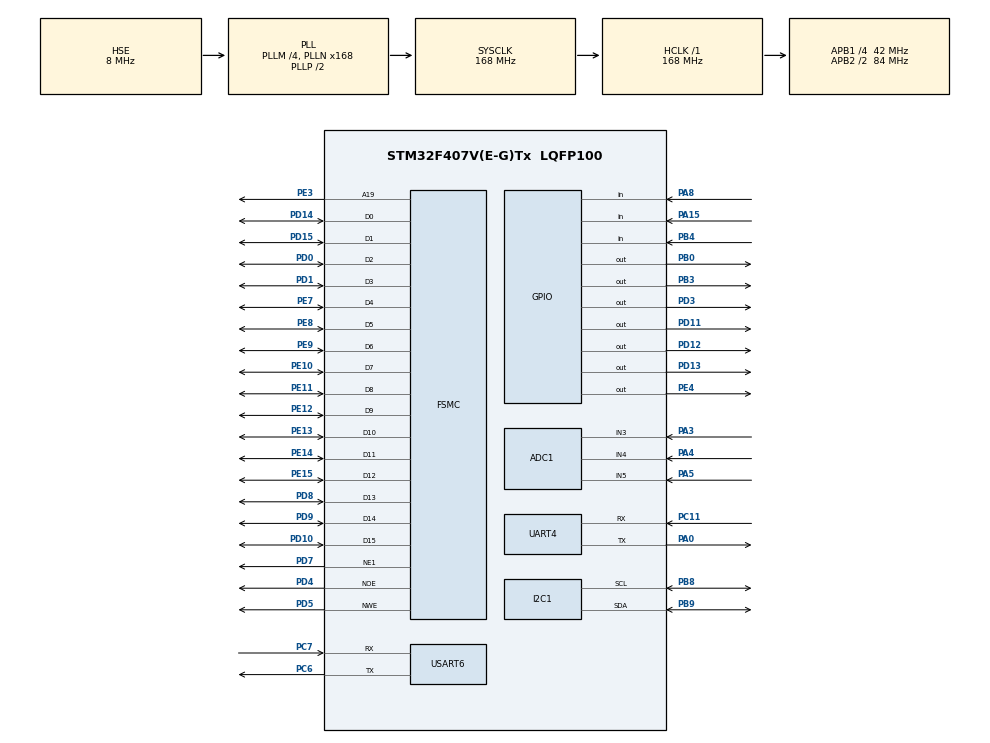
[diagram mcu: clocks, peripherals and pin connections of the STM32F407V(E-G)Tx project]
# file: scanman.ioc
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ADC1.Channel-0\#ChannelRegularConversion=ADC_CHANNEL_3
ADC1.Channel-1\#ChannelInjectedConversion=ADC_CHANNEL_3
ADC1.Channel-2\#ChannelInjectedConversion=ADC_CHANNEL_4
ADC1.Channel-3\#ChannelInjectedConversion=ADC_CHANNEL_5
ADC1.InjNumberOfConversion=3
ADC1.InjectedOffset-1\#ChannelInjectedConversion=0
ADC1.InjectedOffset-2\#ChannelInjectedConversion=0
ADC1.InjectedOffset-3\#ChannelInjectedConversion=0
ADC1.NbrOfConversionFlag=1
ADC1.Rank-0\#ChannelRegularConversion=1
ADC1.Rank-1\#ChannelInjectedConversion=1
ADC1.Rank-2\#ChannelInjectedConversion=2
ADC1.Rank-3\#ChannelInjectedConversion=3
ADC1.SamplingTime-0\#ChannelRegularConversion=ADC_SAMPLETIME_3CYCLES
ADC1.SamplingTime-1\#ChannelInjectedConversion=ADC_SAMPLETIME_3CYCLES
ADC1.SamplingTime-2\#ChannelInjectedConversion=ADC_SAMPLETIME_3CYCLES
ADC1.SamplingTime-3\#ChannelInjectedConversion=ADC_SAMPLETIME_3CYCLES
ADC1.master=1
FSMC.AddressSetupTime1=1
FSMC.BusTurnAroundDuration1=0
FSMC.DataSetupTime1=9
Mcu.Family=STM32F4
Mcu.Name=STM32F407V(E-G)Tx
Mcu.Package=LQFP100
NVIC.PriorityGroup=NVIC_PRIORITYGROUP_4
NVIC.UART4_IRQn=true\:0\:0\:false\:false\:true\:true
NVIC.USART6_IRQn=true\:0\:0\:false\:false\:true\:true
PA0-WKUP.Mode=Asynchronous
PA0-WKUP.Signal=UART4_TX
PA13.Mode=Serial_Wire
PA13.Signal=SYS_JTMS-SWDIO
PA14.Mode=Serial_Wire
PA14.Signal=SYS_JTCK-SWCLK
PA15.GPIO_PuPd=GPIO_PULLUP
PA15.Signal=GPIO_Input
PA3.Signal=ADCx_IN3
PA4.Signal=ADCx_IN4
PA5.Signal=ADCx_IN5
PA8.GPIO_PuPd=GPIO_PULLUP
PA8.Signal=GPIO_Input
PB0.PinState=GPIO_PIN_RESET
PB0.Signal=GPIO_Output
PB3.PinState=GPIO_PIN_SET
PB3.Signal=GPIO_Output
PB4.Signal=GPIO_Input
PB8.Mode=I2C
PB8.Signal=I2C1_SCL
PB9.Mode=I2C
PB9.Signal=I2C1_SDA
PC11.Mode=Asynchronous
PC11.Signal=UART4_RX
PC6.Mode=Asynchronous
PC6.Signal=USART6_TX
PC7.Mode=Asynchronous
PC7.Signal=USART6_RX
PD0.Mode=16b-d1
PD0.Signal=FSMC_D2
PD1.Mode=16b-d1
PD1.Signal=FSMC_D3
PD10.Mode=16b-d1
PD10.Signal=FSMC_D15
PD11.Signal=GPIO_Output
PD12.Signal=GPIO_Output
PD13.Signal=GPIO_Output
PD14.Mode=16b-d1
PD14.Signal=FSMC_D0
PD15.Mode=16b-d1
PD15.Signal=FSMC_D1
PD3.Signal=GPIO_Output
PD4.Mode=Lcd1
PD4.Signal=FSMC_NOE
PD5.Mode=Lcd1
PD5.Signal=FSMC_NWE
PD7.Mode=NorPsramChipSelect1_1
PD7.Signal=FSMC_NE1
PD8.Mode=16b-d1
PD8.Signal=FSMC_D13
PD9.Mode=16b-d1
PD9.Signal=FSMC_D14
PE10.Mode=16b-d1
PE10.Signal=FSMC_D7
PE11.Mode=16b-d1
PE11.Signal=FSMC_D8
PE12.Mode=16b-d1
PE12.Signal=FSMC_D9
PE13.Mode=16b-d1
PE13.Signal=FSMC_D10
PE14.Mode=16b-d1
PE14.Signal=FSMC_D11
PE15.Mode=16b-d1
PE15.Signal=FSMC_D12
PE3.Mode=A19_1
PE3.Signal=FSMC_A19
PE4.Signal=GPIO_Output
PE7.Mode=16b-d1
PE7.Signal=FSMC_D4
PE8.Mode=16b-d1
PE8.Signal=FSMC_D5
PE9.Mode=16b-d1
PE9.Signal=FSMC_D6
PH0-OSC_IN.Mode=HSE-External-Oscillator
PH0-OSC_IN.Signal=RCC_OSC_IN
PH1-OSC_OUT.Mode=HSE-External-Oscillator
PH1-OSC_OUT.Signal=RCC_OSC_OUT
ProjectManager.HeapSize=0x200
ProjectManager.StackSize=0x400
ProjectManager.TargetToolchain=EWARM V8
RCC.48MHZClocksFreq_Value=84000000
RCC.AHBFreq_Value=168000000
RCC.APB1CLKDivider=RCC_HCLK_DIV4
RCC.APB1Freq_Value=42000000
RCC.APB1TimFreq_Value=84000000
RCC.APB2CLKDivider=RCC_HCLK_DIV2
RCC.APB2Freq_Value=84000000
RCC.APB2TimFreq_Value=168000000
RCC.CortexFreq_Value=168000000
RCC.HCLKFreq_Value=168000000
RCC.HSE_VALUE=8000000
RCC.HSI_VALUE=16000000
RCC.LSE_VALUE=32768
RCC.PLLM=4
RCC.PLLN=168
RCC.PLLSourceVirtual=RCC_PLLSOURCE_HSE
RCC.SYSCLKFreq_VALUE=168000000
RCC.SYSCLKSource=RCC_SYSCLKSOURCE_PLLCLK
RCC.VCOOutputFreq_Value=336000000
SH.ADCx_IN3.0=ADC1_IN3,IN3
SH.ADCx_IN4.0=ADC1_IN4,IN4
SH.ADCx_IN5.0=ADC1_IN5,IN5
UART4.VirtualMode=Asynchronous
USART6.VirtualMode=VM_ASYNC
board=custom

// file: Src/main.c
/**
  ******************************************************************************
  * @file           : main.c
  * @brief          : Main program body
  ******************************************************************************
  ** This notice applies to any and all portions of this file
  * that are not between comment pairs USER CODE BEGIN and
  * USER CODE END. Other portions of this file, whether
  * inserted by the user or by software development tools
  * are owned by their respective copyright owners.
  *
  * COPYRIGHT(c) 2019 STMicroelectronics
  *
  * Redistribution and use in source and binary forms, with or without modification,
  * are permitted provided that the following conditions are met:
  *   1. Redistributions of source code must retain the above copyright notice,
  *      this list of conditions and the following disclaimer.
  *   2. Redistributions in binary form must reproduce the above copyright notice,
  *      this list of conditions and the following disclaimer in the documentation
  *      and/or other materials provided with the distribution.
  *   3. Neither the name of STMicroelectronics nor the names of its contributors
  *      may be used to endorse or promote products derived from this software
  *      without specific prior written permission.
  *
  * THIS SOFTWARE IS PROVIDED BY THE COPYRIGHT HOLDERS AND CONTRIBUTORS "AS IS"
  * AND ANY EXPRESS OR IMPLIED WARRANTIES, INCLUDING, BUT NOT LIMITED TO, THE
  * IMPLIED WARRANTIES OF MERCHANTABILITY AND FITNESS FOR A PARTICULAR PURPOSE ARE
  * DISCLAIMED. IN NO EVENT SHALL THE COPYRIGHT HOLDER OR CONTRIBUTORS BE LIABLE
  * FOR ANY DIRECT, INDIRECT, INCIDENTAL, SPECIAL, EXEMPLARY, OR CONSEQUENTIAL
  * DAMAGES (INCLUDING, BUT NOT LIMITED TO, PROCUREMENT OF SUBSTITUTE GOODS OR
  * SERVICES; LOSS OF USE, DATA, OR PROFITS; OR BUSINESS INTERRUPTION) HOWEVER
  * CAUSED AND ON ANY THEORY OF LIABILITY, WHETHER IN CONTRACT, STRICT LIABILITY,
  * OR TORT (INCLUDING NEGLIGENCE OR OTHERWISE) ARISING IN ANY WAY OUT OF THE USE
  * OF THIS SOFTWARE, EVEN IF ADVISED OF THE POSSIBILITY OF SUCH DAMAGE.
  *
  ******************************************************************************
  */
#include "main.h"
#include "stm32f4xx_hal.h"

/* USER CODE BEGIN Includes */
//#include "Variables.c"
uint8_t pData[4]={0};

//char getUart[15]={0};
/* USER CODE END Includes */

ADC_HandleTypeDef hadc1;

I2C_HandleTypeDef hi2c1;

UART_HandleTypeDef huart4;
UART_HandleTypeDef huart6;

SRAM_HandleTypeDef hsram1;

/* USER CODE BEGIN PV */
/* Private variables ---------------------------------------------------------*/

/* USER CODE END PV */

void SystemClock_Config(void);
static void MX_GPIO_Init(void);
static void MX_FSMC_Init(void);
static void MX_ADC1_Init(void);
static void MX_UART4_Init(void);
static void MX_USART6_UART_Init(void);
static void MX_I2C1_Init(void);

/* USER CODE BEGIN PFP */
/* Private function prototypes -----------------------------------------------*/

/* USER CODE END PFP */

 int main(void)
{

  /* MCU Configuration----------------------------------------------------------*/

  /* Reset of all peripherals, Initializes the Flash interface and the Systick. */
  HAL_Init();

  /* Configure the system clock */
  SystemClock_Config();

  /* Initialize all configured peripherals */
  MX_GPIO_Init();
  MX_FSMC_Init();
  MX_ADC1_Init();
  MX_UART4_Init();
  MX_USART6_UART_Init();
  MX_I2C1_Init();
  /* USER CODE BEGIN 2 */

  HAL_I2C_Master_Receive(&hi2c1, 0x82, pData, 4, (uint32_t)10000);
  ScanMan(huart6,hadc1);
  /* USER CODE END 2 */

  /* Infinite loop */
  while (1)
  {

  }

}

void SystemClock_Config(void)
{

  RCC_OscInitTypeDef RCC_OscInitStruct;
  RCC_ClkInitTypeDef RCC_ClkInitStruct;

    /**Configure the main internal regulator output voltage
    */
  __HAL_RCC_PWR_CLK_ENABLE();

  __HAL_PWR_VOLTAGESCALING_CONFIG(PWR_REGULATOR_VOLTAGE_SCALE1);

    /**Initializes the CPU, AHB and APB busses clocks
    */
  RCC_OscInitStruct.OscillatorType = RCC_OSCILLATORTYPE_HSE;
  RCC_OscInitStruct.HSEState = RCC_HSE_ON;
  RCC_OscInitStruct.PLL.PLLState = RCC_PLL_ON;
  RCC_OscInitStruct.PLL.PLLSource = RCC_PLLSOURCE_HSE;
  RCC_OscInitStruct.PLL.PLLM = 4;
  RCC_OscInitStruct.PLL.PLLN = 168;
  RCC_OscInitStruct.PLL.PLLP = RCC_PLLP_DIV2;
  RCC_OscInitStruct.PLL.PLLQ = 4;
  if (HAL_RCC_OscConfig(&RCC_OscInitStruct) != HAL_OK)
  {
    _Error_Handler(__FILE__, __LINE__);
  }

    /**Initializes the CPU, AHB and APB busses clocks
    */
  RCC_ClkInitStruct.ClockType = RCC_CLOCKTYPE_HCLK|RCC_CLOCKTYPE_SYSCLK
                              |RCC_CLOCKTYPE_PCLK1|RCC_CLOCKTYPE_PCLK2;
  RCC_ClkInitStruct.SYSCLKSource = RCC_SYSCLKSOURCE_PLLCLK;
  RCC_ClkInitStruct.AHBCLKDivider = RCC_SYSCLK_DIV1;
  RCC_ClkInitStruct.APB1CLKDivider = RCC_HCLK_DIV4;
  RCC_ClkInitStruct.APB2CLKDivider = RCC_HCLK_DIV2;

  if (HAL_RCC_ClockConfig(&RCC_ClkInitStruct, FLASH_LATENCY_5) != HAL_OK)
  {
    _Error_Handler(__FILE__, __LINE__);
  }

    /**Configure the Systick interrupt time
    */
  HAL_SYSTICK_Config(HAL_RCC_GetHCLKFreq()/1000);

    /**Configure the Systick
    */
  HAL_SYSTICK_CLKSourceConfig(SYSTICK_CLKSOURCE_HCLK);

  /* SysTick_IRQn interrupt configuration */
  HAL_NVIC_SetPriority(SysTick_IRQn, 0, 0);
}

/* ADC1 init function */
static void MX_ADC1_Init(void)
{

  ADC_ChannelConfTypeDef sConfig;
  ADC_InjectionConfTypeDef sConfigInjected;

    /**Configure the global features of the ADC (Clock, Resolution, Data Alignment and number of conversion)
    */
  hadc1.Instance = ADC1;
  hadc1.Init.ClockPrescaler = ADC_CLOCK_SYNC_PCLK_DIV4;
  hadc1.Init.Resolution = ADC_RESOLUTION_12B;
  hadc1.Init.ScanConvMode = ENABLE;
  hadc1.Init.ContinuousConvMode = DISABLE;
  hadc1.Init.DiscontinuousConvMode = DISABLE;
  hadc1.Init.ExternalTrigConvEdge = ADC_EXTERNALTRIGCONVEDGE_NONE;
  hadc1.Init.ExternalTrigConv = ADC_SOFTWARE_START;
  hadc1.Init.DataAlign = ADC_DATAALIGN_RIGHT;
  hadc1.Init.NbrOfConversion = 1;
  hadc1.Init.DMAContinuousRequests = DISABLE;
  hadc1.Init.EOCSelection = ADC_EOC_SINGLE_CONV;
  if (HAL_ADC_Init(&hadc1) != HAL_OK)
  {
    _Error_Handler(__FILE__, __LINE__);
  }

    /**Configure for the selected ADC regular channel its corresponding rank in the sequencer and its sample time.
    */
  sConfig.Channel = ADC_CHANNEL_3;
  sConfig.Rank = 1;
  sConfig.SamplingTime = ADC_SAMPLETIME_3CYCLES;
  if (HAL_ADC_ConfigChannel(&hadc1, &sConfig) != HAL_OK)
  {
    _Error_Handler(__FILE__, __LINE__);
  }

    /**Configures for the selected ADC injected channel its corresponding rank in the sequencer and its sample time
    */
  sConfigInjected.InjectedChannel = ADC_CHANNEL_3;
  sConfigInjected.InjectedRank = 1;
  sConfigInjected.InjectedNbrOfConversion = 3;
  sConfigInjected.InjectedSamplingTime = ADC_SAMPLETIME_3CYCLES;
  sConfigInjected.ExternalTrigInjecConvEdge = ADC_EXTERNALTRIGINJECCONVEDGE_NONE;
  sConfigInjected.ExternalTrigInjecConv = ADC_INJECTED_SOFTWARE_START;
  sConfigInjected.AutoInjectedConv = DISABLE;
  sConfigInjected.InjectedDiscontinuousConvMode = DISABLE;
  sConfigInjected.InjectedOffset = 0;
  if (HAL_ADCEx_InjectedConfigChannel(&hadc1, &sConfigInjected) != HAL_OK)
  {
    _Error_Handler(__FILE__, __LINE__);
  }

    /**Configures for the selected ADC injected channel its corresponding rank in the sequencer and its sample time
    */
  sConfigInjected.InjectedChannel = ADC_CHANNEL_4;
  sConfigInjected.InjectedRank = 2;
  if (HAL_ADCEx_InjectedConfigChannel(&hadc1, &sConfigInjected) != HAL_OK)
  {
    _Error_Handler(__FILE__, __LINE__);
  }

    /**Configures for the selected ADC injected channel its corresponding rank in the sequencer and its sample time
    */
  sConfigInjected.InjectedChannel = ADC_CHANNEL_5;
  sConfigInjected.InjectedRank = 3;
  if (HAL_ADCEx_InjectedConfigChannel(&hadc1, &sConfigInjected) != HAL_OK)
  {
    _Error_Handler(__FILE__, __LINE__);
  }

}

/* I2C1 init function */
static void MX_I2C1_Init(void)
{

  hi2c1.Instance = I2C1;
  hi2c1.Init.ClockSpeed = 100000;
  hi2c1.Init.DutyCycle = I2C_DUTYCYCLE_2;
  hi2c1.Init.OwnAddress1 = 0;
  hi2c1.Init.AddressingMode = I2C_ADDRESSINGMODE_7BIT;
  hi2c1.Init.DualAddressMode = I2C_DUALADDRESS_DISABLE;
  hi2c1.Init.OwnAddress2 = 0;
  hi2c1.Init.GeneralCallMode = I2C_GENERALCALL_DISABLE;
  hi2c1.Init.NoStretchMode = I2C_NOSTRETCH_DISABLE;
  if (HAL_I2C_Init(&hi2c1) != HAL_OK)
  {
    _Error_Handler(__FILE__, __LINE__);
  }

}

/* UART4 init function */
static void MX_UART4_Init(void)
{

  huart4.Instance = UART4;
  huart4.Init.BaudRate = 115200;
  huart4.Init.WordLength = UART_WORDLENGTH_8B;
  huart4.Init.StopBits = UART_STOPBITS_1;
  huart4.Init.Parity = UART_PARITY_NONE;
  huart4.Init.Mode = UART_MODE_TX_RX;
  huart4.Init.HwFlowCtl = UART_HWCONTROL_NONE;
  huart4.Init.OverSampling = UART_OVERSAMPLING_16;
  if (HAL_UART_Init(&huart4) != HAL_OK)
  {
    _Error_Handler(__FILE__, __LINE__);
  }

}

/* USART6 init function */
static void MX_USART6_UART_Init(void)
{

  huart6.Instance = USART6;
  huart6.Init.BaudRate = 115200;
  huart6.Init.WordLength = UART_WORDLENGTH_8B;
  huart6.Init.StopBits = UART_STOPBITS_1;
  huart6.Init.Parity = UART_PARITY_NONE;
  huart6.Init.Mode = UART_MODE_TX_RX;
  huart6.Init.HwFlowCtl = UART_HWCONTROL_NONE;
  huart6.Init.OverSampling = UART_OVERSAMPLING_16;
  if (HAL_UART_Init(&huart6) != HAL_OK)
  {
    _Error_Handler(__FILE__, __LINE__);
  }

}

/** Configure pins as
        * Analog
        * Input
        * Output
        * EVENT_OUT
        * EXTI
*/
static void MX_GPIO_Init(void)
{

  GPIO_InitTypeDef GPIO_InitStruct;

  /* GPIO Ports Clock Enable */
  __HAL_RCC_GPIOE_CLK_ENABLE();
  __HAL_RCC_GPIOH_CLK_ENABLE();
  __HAL_RCC_GPIOA_CLK_ENABLE();
  __HAL_RCC_GPIOB_CLK_ENABLE();
  __HAL_RCC_GPIOD_CLK_ENABLE();
  __HAL_RCC_GPIOC_CLK_ENABLE();

  /*Configure GPIO pin Output Level */
  HAL_GPIO_WritePin(GPIOE, GPIO_PIN_4, GPIO_PIN_RESET);

  /*Configure GPIO pin Output Level */
  HAL_GPIO_WritePin(GPIOB, GPIO_PIN_0, GPIO_PIN_RESET);

  /*Configure GPIO pin Output Level */
  HAL_GPIO_WritePin(GPIOD, GPIO_PIN_11|GPIO_PIN_12|GPIO_PIN_13|GPIO_PIN_3, GPIO_PIN_RESET);

  /*Configure GPIO pin Output Level */
  HAL_GPIO_WritePin(GPIOB, GPIO_PIN_3, GPIO_PIN_SET);

  /*Configure GPIO pin : PE4 */
  GPIO_InitStruct.Pin = GPIO_PIN_4;
  GPIO_InitStruct.Mode = GPIO_MODE_OUTPUT_PP;
  GPIO_InitStruct.Pull = GPIO_NOPULL;
  GPIO_InitStruct.Speed = GPIO_SPEED_FREQ_LOW;
  HAL_GPIO_Init(GPIOE, &GPIO_InitStruct);

  /*Configure GPIO pins : PB0 PB3 */
  GPIO_InitStruct.Pin = GPIO_PIN_0|GPIO_PIN_3;
  GPIO_InitStruct.Mode = GPIO_MODE_OUTPUT_PP;
  GPIO_InitStruct.Pull = GPIO_NOPULL;
  GPIO_InitStruct.Speed = GPIO_SPEED_FREQ_LOW;
  HAL_GPIO_Init(GPIOB, &GPIO_InitStruct);

  /*Configure GPIO pins : PD11 PD12 PD13 PD3 */
  GPIO_InitStruct.Pin = GPIO_PIN_11|GPIO_PIN_12|GPIO_PIN_13|GPIO_PIN_3;
  GPIO_InitStruct.Mode = GPIO_MODE_OUTPUT_PP;
  GPIO_InitStruct.Pull = GPIO_NOPULL;
  GPIO_InitStruct.Speed = GPIO_SPEED_FREQ_LOW;
  HAL_GPIO_Init(GPIOD, &GPIO_InitStruct);

  /*Configure GPIO pins : PA8 PA15 */
  GPIO_InitStruct.Pin = GPIO_PIN_8|GPIO_PIN_15;
  GPIO_InitStruct.Mode = GPIO_MODE_INPUT;
  GPIO_InitStruct.Pull = GPIO_PULLUP;
  HAL_GPIO_Init(GPIOA, &GPIO_InitStruct);

  /*Configure GPIO pin : PB4 */
  GPIO_InitStruct.Pin = GPIO_PIN_4;
  GPIO_InitStruct.Mode = GPIO_MODE_INPUT;
  GPIO_InitStruct.Pull = GPIO_NOPULL;
  HAL_GPIO_Init(GPIOB, &GPIO_InitStruct);

}

/* FSMC initialization function */
static void MX_FSMC_Init(void)
{
  FSMC_NORSRAM_TimingTypeDef Timing;

  /** Perform the SRAM1 memory initialization sequence
  */
  hsram1.Instance = FSMC_NORSRAM_DEVICE;
  hsram1.Extended = FSMC_NORSRAM_EXTENDED_DEVICE;
  /* hsram1.Init */
  hsram1.Init.NSBank = FSMC_NORSRAM_BANK1;
  hsram1.Init.DataAddressMux = FSMC_DATA_ADDRESS_MUX_DISABLE;
  hsram1.Init.MemoryType = FSMC_MEMORY_TYPE_SRAM;
  hsram1.Init.MemoryDataWidth = FSMC_NORSRAM_MEM_BUS_WIDTH_16;
  hsram1.Init.BurstAccessMode = FSMC_BURST_ACCESS_MODE_DISABLE;
  hsram1.Init.WaitSignalPolarity = FSMC_WAIT_SIGNAL_POLARITY_LOW;
  hsram1.Init.WrapMode = FSMC_WRAP_MODE_DISABLE;
  hsram1.Init.WaitSignalActive = FSMC_WAIT_TIMING_BEFORE_WS;
  hsram1.Init.WriteOperation = FSMC_WRITE_OPERATION_ENABLE;
  hsram1.Init.WaitSignal = FSMC_WAIT_SIGNAL_DISABLE;
  hsram1.Init.ExtendedMode = FSMC_EXTENDED_MODE_DISABLE;
  hsram1.Init.AsynchronousWait = FSMC_ASYNCHRONOUS_WAIT_DISABLE;
  hsram1.Init.WriteBurst = FSMC_WRITE_BURST_DISABLE;
  hsram1.Init.PageSize = FSMC_PAGE_SIZE_NONE;
  /* Timing */
  Timing.AddressSetupTime = 1;
  Timing.AddressHoldTime = 15;
  Timing.DataSetupTime = 9;
  Timing.BusTurnAroundDuration = 0;
  Timing.CLKDivision = 16;
  Timing.DataLatency = 17;
  Timing.AccessMode = FSMC_ACCESS_MODE_A;
  /* ExtTiming */

  if (HAL_SRAM_Init(&hsram1, &Timing, NULL) != HAL_OK)
  {
    _Error_Handler(__FILE__, __LINE__);
  }

}

void _Error_Handler(char *file, int line)
{
  while(1)
  {
  }
}

/************************ (C) COPYRIGHT STMicroelectronics *****END OF FILE****/
